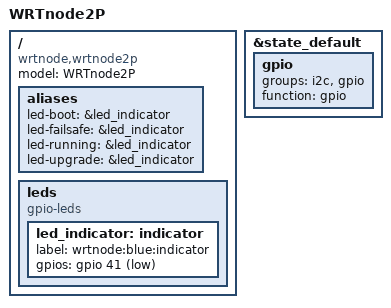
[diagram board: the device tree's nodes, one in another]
/dts-v1/;

#include "mt7628an_wrtnode_wrtnode2.dtsi"

/ {
	compatible = "wrtnode,wrtnode2p", "wrtnode,wrtnode2", "mediatek,mt7628an-soc";
	model = "WRTnode2P";

	aliases {
		led-boot = &led_indicator;
		led-failsafe = &led_indicator;
		led-running = &led_indicator;
		led-upgrade = &led_indicator;
	};

	leds {
		compatible = "gpio-leds";

		led_indicator: indicator {
			label = "wrtnode:blue:indicator";
			gpios = <&gpio 41 GPIO_ACTIVE_LOW>;
		};
	};
};

&state_default {
	gpio {
		groups = "i2c", "gpio";
		function = "gpio";
	};
};
